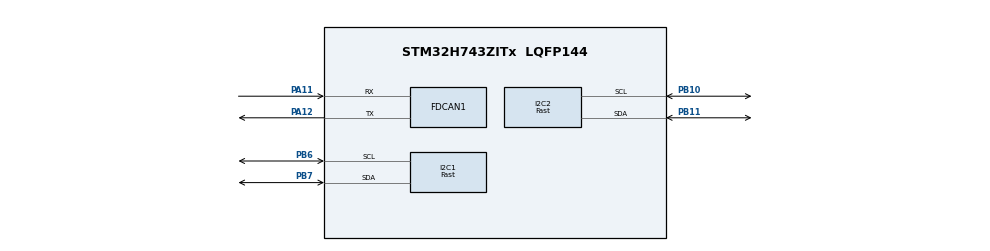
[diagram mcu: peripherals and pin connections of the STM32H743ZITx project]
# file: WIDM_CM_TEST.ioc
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CORTEX_M7.AccessPermission-Cortex_Memory_Protection_Unit_Region0_Settings=MPU_REGION_FULL_ACCESS
CORTEX_M7.AccessPermission-Cortex_Memory_Protection_Unit_Region1_Settings=MPU_REGION_FULL_ACCESS
CORTEX_M7.BaseAddress-Cortex_Memory_Protection_Unit_Region0_Settings=0x30000000
CORTEX_M7.BaseAddress-Cortex_Memory_Protection_Unit_Region1_Settings=0x38000000
CORTEX_M7.CPU_DCache=Enabled
CORTEX_M7.CPU_ICache=Enabled
CORTEX_M7.DisableExec-Cortex_Memory_Protection_Unit_Region0_Settings=MPU_INSTRUCTION_ACCESS_DISABLE
CORTEX_M7.DisableExec-Cortex_Memory_Protection_Unit_Region1_Settings=MPU_INSTRUCTION_ACCESS_DISABLE
CORTEX_M7.Enable-Cortex_Memory_Protection_Unit_Region0_Settings=MPU_REGION_ENABLE
CORTEX_M7.Enable-Cortex_Memory_Protection_Unit_Region1_Settings=MPU_REGION_ENABLE
CORTEX_M7.IsShareable-Cortex_Memory_Protection_Unit_Region0_Settings=MPU_ACCESS_SHAREABLE
CORTEX_M7.IsShareable-Cortex_Memory_Protection_Unit_Region1_Settings=MPU_ACCESS_SHAREABLE
CORTEX_M7.MPU_Control=MPU_HFNMI_PRIVDEF
CORTEX_M7.Size-Cortex_Memory_Protection_Unit_Region0_Settings=MPU_REGION_SIZE_128KB
CORTEX_M7.Size-Cortex_Memory_Protection_Unit_Region1_Settings=MPU_REGION_SIZE_64KB
CORTEX_M7.TypeExtField-Cortex_Memory_Protection_Unit_Region0_Settings=MPU_TEX_LEVEL1
CORTEX_M7.TypeExtField-Cortex_Memory_Protection_Unit_Region1_Settings=MPU_TEX_LEVEL1
CORTEX_M7.default_mode_Activation=0
Dma.I2C1_RX.0.Direction=DMA_PERIPH_TO_MEMORY
Dma.I2C1_RX.0.EventEnable=DISABLE
Dma.I2C1_RX.0.FIFOMode=DMA_FIFOMODE_DISABLE
Dma.I2C1_RX.0.Instance=DMA1_Stream0
Dma.I2C1_RX.0.MemDataAlignment=DMA_MDATAALIGN_BYTE
Dma.I2C1_RX.0.MemInc=DMA_MINC_ENABLE
Dma.I2C1_RX.0.Mode=DMA_NORMAL
Dma.I2C1_RX.0.PeriphDataAlignment=DMA_PDATAALIGN_BYTE
Dma.I2C1_RX.0.PeriphInc=DMA_PINC_DISABLE
Dma.I2C1_RX.0.Polarity=HAL_DMAMUX_REQ_GEN_RISING
Dma.I2C1_RX.0.Priority=DMA_PRIORITY_LOW
Dma.I2C1_RX.0.RequestNumber=1
Dma.I2C1_RX.0.SignalID=NONE
Dma.I2C1_RX.0.SyncEnable=DISABLE
Dma.I2C1_RX.0.SyncPolarity=HAL_DMAMUX_SYNC_NO_EVENT
Dma.I2C1_RX.0.SyncRequestNumber=1
Dma.I2C1_RX.0.SyncSignalID=NONE
Dma.I2C2_RX.1.Direction=DMA_PERIPH_TO_MEMORY
Dma.I2C2_RX.1.EventEnable=DISABLE
Dma.I2C2_RX.1.FIFOMode=DMA_FIFOMODE_DISABLE
Dma.I2C2_RX.1.Instance=DMA2_Stream0
Dma.I2C2_RX.1.MemDataAlignment=DMA_MDATAALIGN_BYTE
Dma.I2C2_RX.1.MemInc=DMA_MINC_ENABLE
Dma.I2C2_RX.1.Mode=DMA_NORMAL
Dma.I2C2_RX.1.PeriphDataAlignment=DMA_PDATAALIGN_BYTE
Dma.I2C2_RX.1.PeriphInc=DMA_PINC_DISABLE
Dma.I2C2_RX.1.Polarity=HAL_DMAMUX_REQ_GEN_RISING
Dma.I2C2_RX.1.Priority=DMA_PRIORITY_LOW
Dma.I2C2_RX.1.RequestNumber=1
Dma.I2C2_RX.1.SignalID=NONE
Dma.I2C2_RX.1.SyncEnable=DISABLE
Dma.I2C2_RX.1.SyncPolarity=HAL_DMAMUX_SYNC_NO_EVENT
Dma.I2C2_RX.1.SyncRequestNumber=1
Dma.I2C2_RX.1.SyncSignalID=NONE
Dma.Request0=I2C1_RX
Dma.Request1=I2C2_RX
FDCAN1.AutoRetransmission=ENABLE
FDCAN1.CalculateBaudRateNominal=500000
FDCAN1.CalculateTimeBitNominal=2000
FDCAN1.CalculateTimeQuantumNominal=12.5
FDCAN1.DataSyncJumpWidth=4
FDCAN1.DataTimeSeg1=11
FDCAN1.DataTimeSeg2=4
FDCAN1.FrameFormat=FDCAN_FRAME_FD_BRS
FDCAN1.NominalPrescaler=1
FDCAN1.NominalSyncJumpWidth=32
FDCAN1.NominalTimeSeg1=127
FDCAN1.NominalTimeSeg2=32
FDCAN1.RxBufferSize=FDCAN_DATA_BYTES_64
FDCAN1.RxBuffersNbr=4
FDCAN1.RxFifo0ElmtSize=FDCAN_DATA_BYTES_64
FDCAN1.RxFifo0ElmtsNbr=4
FDCAN1.RxFifo1ElmtSize=FDCAN_DATA_BYTES_64
FDCAN1.RxFifo1ElmtsNbr=4
FDCAN1.StdFiltersNbr=1
FDCAN1.TransmitPause=ENABLE
FDCAN1.TxBuffersNbr=4
FDCAN1.TxElmtSize=FDCAN_DATA_BYTES_64
FDCAN1.TxEventsNbr=4
FDCAN1.TxFifoQueueElmtsNbr=16
FDCAN1.TxFifoQueueMode=FDCAN_TX_QUEUE_OPERATION
I2C1.I2C_Speed_Mode=I2C_Fast
I2C1.Timing=0x00B03FDB
I2C2.I2C_Speed_Mode=I2C_Fast
I2C2.Timing=0x00B03FDB
Mcu.Family=STM32H7
Mcu.Name=STM32H743ZITx
Mcu.Package=LQFP144
NVIC.DMA1_Stream0_IRQn=true\:0\:0\:false\:false\:true\:false\:true\:true
NVIC.DMA2_Stream0_IRQn=true\:0\:0\:false\:false\:true\:false\:true\:true
NVIC.FDCAN1_IT0_IRQn=true\:1\:0\:true\:false\:true\:true\:true\:true
NVIC.FDCAN1_IT1_IRQn=true\:1\:0\:true\:false\:true\:true\:true\:true
NVIC.FDCAN_CAL_IRQn=true\:14\:0\:true\:false\:true\:true\:true\:true
NVIC.I2C1_EV_IRQn=true\:1\:0\:true\:false\:true\:true\:true\:true
NVIC.I2C2_EV_IRQn=true\:2\:0\:true\:false\:true\:true\:true\:true
NVIC.PriorityGroup=NVIC_PRIORITYGROUP_4
NVIC.RCC_IRQn=true\:1\:0\:true\:false\:true\:true\:false\:true
NVIC.TIM3_IRQn=true\:1\:0\:true\:false\:true\:true\:true\:true
NVIC.TIM6_DAC_IRQn=true\:5\:0\:true\:false\:true\:true\:true\:true
PA11.Mode=FDCAN_Activate
PA11.Signal=FDCAN1_RX
PA12.Mode=FDCAN_Activate
PA12.Signal=FDCAN1_TX
PA13\ (JTMS/SWDIO).Mode=Serial_Wire
PA13\ (JTMS/SWDIO).Signal=DEBUG_JTMS-SWDIO
PA14\ (JTCK/SWCLK).Mode=Serial_Wire
PA14\ (JTCK/SWCLK).Signal=DEBUG_JTCK-SWCLK
PB10.Mode=I2C
PB10.Signal=I2C2_SCL
PB11.Mode=I2C
PB11.Signal=I2C2_SDA
PB6.Mode=I2C
PB6.Signal=I2C1_SCL
PB7.Mode=I2C
PB7.Signal=I2C1_SDA
PC14-OSC32_IN\ (OSC32_IN).Mode=LSE-External-Oscillator
PC14-OSC32_IN\ (OSC32_IN).Signal=RCC_OSC32_IN
PC15-OSC32_OUT\ (OSC32_OUT).Mode=LSE-External-Oscillator
PC15-OSC32_OUT\ (OSC32_OUT).Signal=RCC_OSC32_OUT
PH0-OSC_IN\ (PH0).Mode=HSE-External-Oscillator
PH0-OSC_IN\ (PH0).Signal=RCC_OSC_IN
PH1-OSC_OUT\ (PH1).Mode=HSE-External-Oscillator
PH1-OSC_OUT\ (PH1).Signal=RCC_OSC_OUT
ProjectManager.HeapSize=0x200
ProjectManager.StackSize=0x400
ProjectManager.TargetToolchain=STM32CubeIDE
RCC.ADCFreq_Value=156250000
RCC.APB1Freq_Value=120000000
RCC.APB2Freq_Value=120000000
RCC.APB3Freq_Value=120000000
RCC.APB4Freq_Value=120000000
RCC.CortexFreq_Value=480000000
RCC.D1PPRE=RCC_APB3_DIV2
RCC.D2PPRE1=RCC_APB1_DIV2
RCC.D2PPRE2=RCC_APB2_DIV2
RCC.D3PPRE=RCC_APB4_DIV2
RCC.DIVM1=5
RCC.DIVM2=4
RCC.DIVN1=192
RCC.DIVN2=50
RCC.DIVQ1=12
RCC.HCLKFreq_Value=240000000
RCC.HPRE=RCC_HCLK_DIV2
RCC.PLL2FRACN=0
RCC.PLL3FRACN=0
RCC.PLLFRACN=0
RCC.PLLSourceVirtual=RCC_PLLSOURCE_HSE
RCC.PWR_Regulator_Voltage_Scale=PWR_REGULATOR_VOLTAGE_SCALE0
RCC.ProductRev=revV
RCC.SYSCLKFreq_VALUE=480000000
RCC.SYSCLKSource=RCC_SYSCLKSOURCE_PLLCLK
RCC.USBFreq_Value=80000000
TIM3.Period=1000-1
TIM3.Prescaler=240-1
TIM6.Period=1000-1
TIM6.Prescaler=240-1
VP_TIM3_VS_ClockSourceINT.Mode=Internal
VP_TIM6_VS_ClockSourceINT.Mode=Enable_Timer
board=custom

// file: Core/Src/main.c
/* USER CODE BEGIN Header */
/**
  ******************************************************************************
  * @file           : main.c
  * @brief          : Main program body
  ******************************************************************************
  * @attention
  *
  * Copyright (c) 2023 STMicroelectronics.
  * All rights reserved.
  *
  * This software is licensed under terms that can be found in the LICENSE file
  * in the root directory of this software component.
  * If no LICENSE file comes with this software, it is provided AS-IS.
  *
  ******************************************************************************
  */
/* USER CODE END Header */
#include "main.h"
#include "dma.h"
#include "fdcan.h"
#include "i2c.h"
#include "tim.h"
#include "gpio.h"

/* USER CODE BEGIN Includes */
#include "msg_hdlr_task.h"
#include "imu_ctrl_task.h"
#include "object_dictionaries.h"
/* USER CODE END Includes */

void SystemClock_Config(void);
static void MPU_Initialize(void);
static void MPU_Config(void);

int main(void)
{

  /* Enable I-Cache---------------------------------------------------------*/
  SCB_EnableICache();

  /* Enable D-Cache---------------------------------------------------------*/
  SCB_EnableDCache();

  /* MCU Configuration--------------------------------------------------------*/

  /* Reset of all peripherals, Initializes the Flash interface and the Systick. */
  HAL_Init();

  /* MPU Configuration--------------------------------------------------------*/
  MPU_Config();

  /* Configure the system clock */
  SystemClock_Config();

  /* Initialize all configured peripherals */
  MX_GPIO_Init();
  MX_DMA_Init();
  MX_I2C1_Init();
  MX_TIM3_Init();
  MX_TIM6_Init();
  MX_FDCAN1_Init();
  MX_I2C2_Init();
  /* USER CODE BEGIN 2 */

  // [For Debug, HCLK = 240MHz, SysClk= 480MHz(USED) //
  CoreDebug->DEMCR &= ~CoreDebug_DEMCR_TRCENA_Msk;
  CoreDebug->DEMCR |= CoreDebug_DEMCR_TRCENA_Msk;
  //DWT->LAR = 0xC5ACCE55;
  DWT->CTRL &= ~DWT_CTRL_CYCCNTENA_Msk;
  DWT->CTRL |= DWT_CTRL_CYCCNTENA_Msk;
  DWT->CYCCNT = 0;

  Create_PDOTable_ObjDictionary();
  Create_SDOTable_ObjDictionary();

  MS_enum = IDLE;

  Init_Imu_Ctrl();
  Init_Msg_Hdlr();

  /* USER CODE END 2 */

  /* Infinite loop */
  while (1)
  {

  }
}

void SystemClock_Config(void)
{
  RCC_OscInitTypeDef RCC_OscInitStruct = {0};
  RCC_ClkInitTypeDef RCC_ClkInitStruct = {0};

  /** Supply configuration update enable
  */
  HAL_PWREx_ConfigSupply(PWR_LDO_SUPPLY);

  /** Configure the main internal regulator output voltage
  */
  __HAL_PWR_VOLTAGESCALING_CONFIG(PWR_REGULATOR_VOLTAGE_SCALE1);

  while(!__HAL_PWR_GET_FLAG(PWR_FLAG_VOSRDY)) {}

  __HAL_RCC_SYSCFG_CLK_ENABLE();
  __HAL_PWR_VOLTAGESCALING_CONFIG(PWR_REGULATOR_VOLTAGE_SCALE0);

  while(!__HAL_PWR_GET_FLAG(PWR_FLAG_VOSRDY)) {}

  /** Initializes the RCC Oscillators according to the specified parameters
  * in the RCC_OscInitTypeDef structure.
  */
  RCC_OscInitStruct.OscillatorType = RCC_OSCILLATORTYPE_HSE;
  RCC_OscInitStruct.HSEState = RCC_HSE_ON;
  RCC_OscInitStruct.PLL.PLLState = RCC_PLL_ON;
  RCC_OscInitStruct.PLL.PLLSource = RCC_PLLSOURCE_HSE;
  RCC_OscInitStruct.PLL.PLLM = 5;
  RCC_OscInitStruct.PLL.PLLN = 192;
  RCC_OscInitStruct.PLL.PLLP = 2;
  RCC_OscInitStruct.PLL.PLLQ = 12;
  RCC_OscInitStruct.PLL.PLLR = 2;
  RCC_OscInitStruct.PLL.PLLRGE = RCC_PLL1VCIRANGE_2;
  RCC_OscInitStruct.PLL.PLLVCOSEL = RCC_PLL1VCOWIDE;
  RCC_OscInitStruct.PLL.PLLFRACN = 0;
  if (HAL_RCC_OscConfig(&RCC_OscInitStruct) != HAL_OK)
  {
    Error_Handler();
  }

  /** Initializes the CPU, AHB and APB buses clocks
  */
  RCC_ClkInitStruct.ClockType = RCC_CLOCKTYPE_HCLK|RCC_CLOCKTYPE_SYSCLK
                              |RCC_CLOCKTYPE_PCLK1|RCC_CLOCKTYPE_PCLK2
                              |RCC_CLOCKTYPE_D3PCLK1|RCC_CLOCKTYPE_D1PCLK1;
  RCC_ClkInitStruct.SYSCLKSource = RCC_SYSCLKSOURCE_PLLCLK;
  RCC_ClkInitStruct.SYSCLKDivider = RCC_SYSCLK_DIV1;
  RCC_ClkInitStruct.AHBCLKDivider = RCC_HCLK_DIV2;
  RCC_ClkInitStruct.APB3CLKDivider = RCC_APB3_DIV2;
  RCC_ClkInitStruct.APB1CLKDivider = RCC_APB1_DIV2;
  RCC_ClkInitStruct.APB2CLKDivider = RCC_APB2_DIV2;
  RCC_ClkInitStruct.APB4CLKDivider = RCC_APB4_DIV2;

  if (HAL_RCC_ClockConfig(&RCC_ClkInitStruct, FLASH_LATENCY_4) != HAL_OK)
  {
    Error_Handler();
  }
}

/* MPU Configuration */

void MPU_Config(void)
{
  MPU_Region_InitTypeDef MPU_InitStruct = {0};

  /* Disables the MPU */
  HAL_MPU_Disable();

  /** Initializes and configures the Region and the memory to be protected
  */
  MPU_InitStruct.Enable = MPU_REGION_ENABLE;
  MPU_InitStruct.Number = MPU_REGION_NUMBER0;
  MPU_InitStruct.BaseAddress = 0x30000000;
  MPU_InitStruct.Size = MPU_REGION_SIZE_128KB;
  MPU_InitStruct.SubRegionDisable = 0x0;
  MPU_InitStruct.TypeExtField = MPU_TEX_LEVEL1;
  MPU_InitStruct.AccessPermission = MPU_REGION_FULL_ACCESS;
  MPU_InitStruct.DisableExec = MPU_INSTRUCTION_ACCESS_DISABLE;
  MPU_InitStruct.IsShareable = MPU_ACCESS_SHAREABLE;
  MPU_InitStruct.IsCacheable = MPU_ACCESS_NOT_CACHEABLE;
  MPU_InitStruct.IsBufferable = MPU_ACCESS_NOT_BUFFERABLE;

  HAL_MPU_ConfigRegion(&MPU_InitStruct);

  /** Initializes and configures the Region and the memory to be protected
  */
  MPU_InitStruct.Number = MPU_REGION_NUMBER1;
  MPU_InitStruct.BaseAddress = 0x38000000;
  MPU_InitStruct.Size = MPU_REGION_SIZE_64KB;

  HAL_MPU_ConfigRegion(&MPU_InitStruct);
  /* Enables the MPU */
  HAL_MPU_Enable(MPU_HFNMI_PRIVDEF);

}

void Error_Handler(void)
{
  __disable_irq();
  while (1)
  {
  }
}
